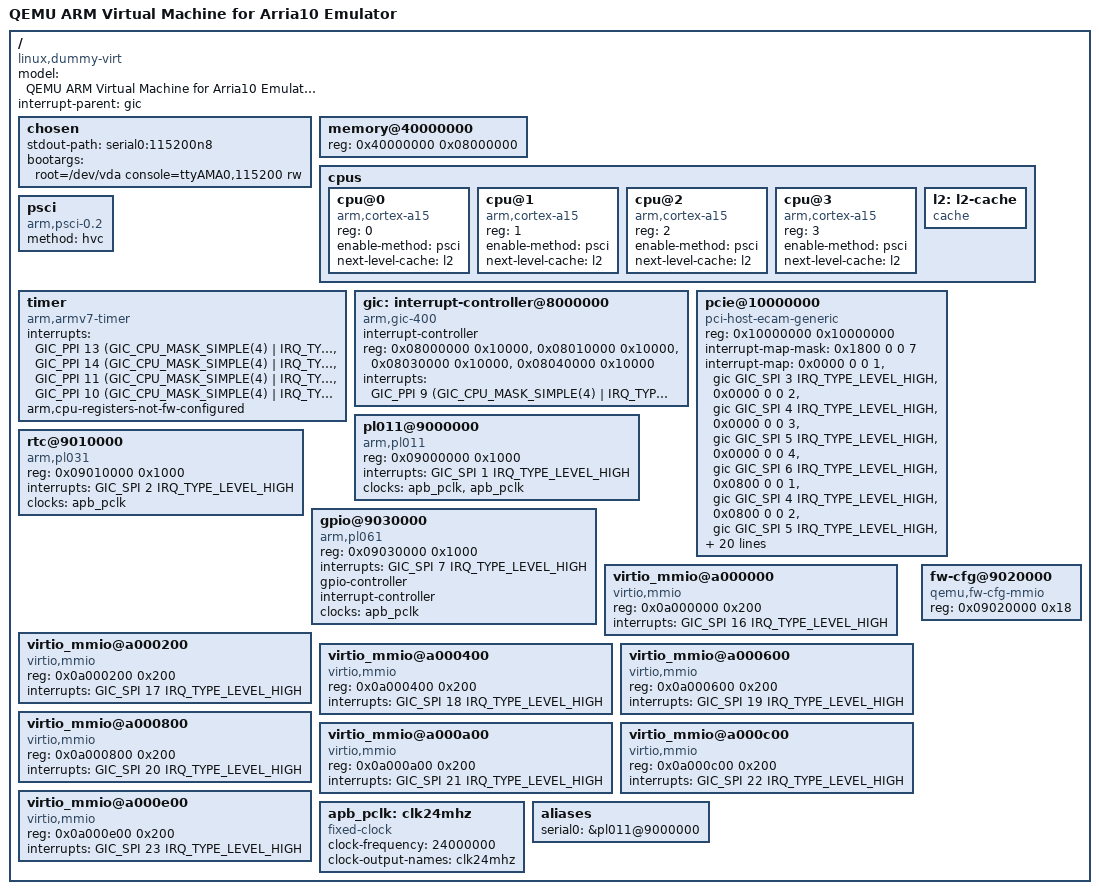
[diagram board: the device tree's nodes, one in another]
/*
 * Device Tree for QEMU ARM virt machine (arria10-emulator)
 * Based on QEMU ARM32 virt machine specification
 */

/dts-v1/;

#include <dt-bindings/interrupt-controller/arm-gic.h>
#include <dt-bindings/gpio/gpio.h>

/ {
	model = "QEMU ARM Virtual Machine for Arria10 Emulator";
	compatible = "linux,dummy-virt";
	#address-cells = <1>;
	#size-cells = <1>;
	interrupt-parent = <&gic>;

	chosen {
		stdout-path = "serial0:115200n8";
		bootargs = "root=/dev/vda console=ttyAMA0,115200 rw";
	};

	memory@40000000 {
		device_type = "memory";
		reg = <0x40000000 0x08000000>; /* 128 MB */
	};

	cpus {
		#address-cells = <1>;
		#size-cells = <0>;

		cpu@0 {
			device_type = "cpu";
			compatible = "arm,cortex-a15";
			reg = <0>;
			enable-method = "psci";
			next-level-cache = <&l2>;
		};

		cpu@1 {
			device_type = "cpu";
			compatible = "arm,cortex-a15";
			reg = <1>;
			enable-method = "psci";
			next-level-cache = <&l2>;
		};

		cpu@2 {
			device_type = "cpu";
			compatible = "arm,cortex-a15";
			reg = <2>;
			enable-method = "psci";
			next-level-cache = <&l2>;
		};

		cpu@3 {
			device_type = "cpu";
			compatible = "arm,cortex-a15";
			reg = <3>;
			enable-method = "psci";
			next-level-cache = <&l2>;
		};

		l2: l2-cache {
			compatible = "cache";
		};
	};

	psci {
		compatible = "arm,psci-0.2";
		method = "hvc";
	};

	timer {
		compatible = "arm,armv7-timer";
		interrupts = <GIC_PPI 13 (GIC_CPU_MASK_SIMPLE(4) | IRQ_TYPE_LEVEL_LOW)>,
			     <GIC_PPI 14 (GIC_CPU_MASK_SIMPLE(4) | IRQ_TYPE_LEVEL_LOW)>,
			     <GIC_PPI 11 (GIC_CPU_MASK_SIMPLE(4) | IRQ_TYPE_LEVEL_LOW)>,
			     <GIC_PPI 10 (GIC_CPU_MASK_SIMPLE(4) | IRQ_TYPE_LEVEL_LOW)>;
		arm,cpu-registers-not-fw-configured;
	};

	gic: interrupt-controller@8000000 {
		compatible = "arm,gic-400";
		#interrupt-cells = <3>;
		#address-cells = <0>;
		interrupt-controller;
		reg = <0x08000000 0x10000>,
		      <0x08010000 0x10000>,
		      <0x08030000 0x10000>,
		      <0x08040000 0x10000>;
		interrupts = <GIC_PPI 9 (GIC_CPU_MASK_SIMPLE(4) | IRQ_TYPE_LEVEL_HIGH)>;
	};

	pcie@10000000 {
		compatible = "pci-host-ecam-generic";
		device_type = "pci";
		#address-cells = <3>;
		#size-cells = <2>;
		#interrupt-cells = <1>;
		reg = <0x10000000 0x10000000>;
		ranges = <0x1000000 0x0 0x0 0x3eff0000 0x0 0x10000>,
			 <0x2000000 0x0 0x10000000 0x10000000 0x0 0x2eff0000>,
			 <0x3000000 0x8 0x0 0x8000000000 0x8 0x0>;
		interrupt-map-mask = <0x1800 0 0 7>;
		interrupt-map = <0x0000 0 0 1 &gic GIC_SPI 3 IRQ_TYPE_LEVEL_HIGH>,
				<0x0000 0 0 2 &gic GIC_SPI 4 IRQ_TYPE_LEVEL_HIGH>,
				<0x0000 0 0 3 &gic GIC_SPI 5 IRQ_TYPE_LEVEL_HIGH>,
				<0x0000 0 0 4 &gic GIC_SPI 6 IRQ_TYPE_LEVEL_HIGH>,
				<0x0800 0 0 1 &gic GIC_SPI 4 IRQ_TYPE_LEVEL_HIGH>,
				<0x0800 0 0 2 &gic GIC_SPI 5 IRQ_TYPE_LEVEL_HIGH>,
				<0x0800 0 0 3 &gic GIC_SPI 6 IRQ_TYPE_LEVEL_HIGH>,
				<0x0800 0 0 4 &gic GIC_SPI 3 IRQ_TYPE_LEVEL_HIGH>,
				<0x1000 0 0 1 &gic GIC_SPI 5 IRQ_TYPE_LEVEL_HIGH>,
				<0x1000 0 0 2 &gic GIC_SPI 6 IRQ_TYPE_LEVEL_HIGH>,
				<0x1000 0 0 3 &gic GIC_SPI 3 IRQ_TYPE_LEVEL_HIGH>,
				<0x1000 0 0 4 &gic GIC_SPI 4 IRQ_TYPE_LEVEL_HIGH>,
				<0x1800 0 0 1 &gic GIC_SPI 6 IRQ_TYPE_LEVEL_HIGH>,
				<0x1800 0 0 2 &gic GIC_SPI 3 IRQ_TYPE_LEVEL_HIGH>,
				<0x1800 0 0 3 &gic GIC_SPI 4 IRQ_TYPE_LEVEL_HIGH>,
				<0x1800 0 0 4 &gic GIC_SPI 5 IRQ_TYPE_LEVEL_HIGH>;
	};

	pl011@9000000 {
		compatible = "arm,pl011", "arm,primecell";
		reg = <0x09000000 0x1000>;
		interrupts = <GIC_SPI 1 IRQ_TYPE_LEVEL_HIGH>;
		clocks = <&apb_pclk>, <&apb_pclk>;
		clock-names = "uartclk", "apb_pclk";
	};

	rtc@9010000 {
		compatible = "arm,pl031", "arm,primecell";
		reg = <0x09010000 0x1000>;
		interrupts = <GIC_SPI 2 IRQ_TYPE_LEVEL_HIGH>;
		clocks = <&apb_pclk>;
		clock-names = "apb_pclk";
	};

	gpio@9030000 {
		compatible = "arm,pl061", "arm,primecell";
		reg = <0x09030000 0x1000>;
		interrupts = <GIC_SPI 7 IRQ_TYPE_LEVEL_HIGH>;
		gpio-controller;
		#gpio-cells = <2>;
		interrupt-controller;
		#interrupt-cells = <2>;
		clocks = <&apb_pclk>;
		clock-names = "apb_pclk";
	};

	virtio_mmio@a000000 {
		compatible = "virtio,mmio";
		reg = <0x0a000000 0x200>;
		interrupts = <GIC_SPI 16 IRQ_TYPE_LEVEL_HIGH>;
	};

	virtio_mmio@a000200 {
		compatible = "virtio,mmio";
		reg = <0x0a000200 0x200>;
		interrupts = <GIC_SPI 17 IRQ_TYPE_LEVEL_HIGH>;
	};

	virtio_mmio@a000400 {
		compatible = "virtio,mmio";
		reg = <0x0a000400 0x200>;
		interrupts = <GIC_SPI 18 IRQ_TYPE_LEVEL_HIGH>;
	};

	virtio_mmio@a000600 {
		compatible = "virtio,mmio";
		reg = <0x0a000600 0x200>;
		interrupts = <GIC_SPI 19 IRQ_TYPE_LEVEL_HIGH>;
	};

	virtio_mmio@a000800 {
		compatible = "virtio,mmio";
		reg = <0x0a000800 0x200>;
		interrupts = <GIC_SPI 20 IRQ_TYPE_LEVEL_HIGH>;
	};

	virtio_mmio@a000a00 {
		compatible = "virtio,mmio";
		reg = <0x0a000a00 0x200>;
		interrupts = <GIC_SPI 21 IRQ_TYPE_LEVEL_HIGH>;
	};

	virtio_mmio@a000c00 {
		compatible = "virtio,mmio";
		reg = <0x0a000c00 0x200>;
		interrupts = <GIC_SPI 22 IRQ_TYPE_LEVEL_HIGH>;
	};

	virtio_mmio@a000e00 {
		compatible = "virtio,mmio";
		reg = <0x0a000e00 0x200>;
		interrupts = <GIC_SPI 23 IRQ_TYPE_LEVEL_HIGH>;
	};

	fw-cfg@9020000 {
		compatible = "qemu,fw-cfg-mmio";
		reg = <0x09020000 0x18>;
	};

	apb_pclk: clk24mhz {
		compatible = "fixed-clock";
		#clock-cells = <0>;
		clock-frequency = <24000000>;
		clock-output-names = "clk24mhz";
	};

	aliases {
		serial0 = &pl011@9000000;
	};
};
